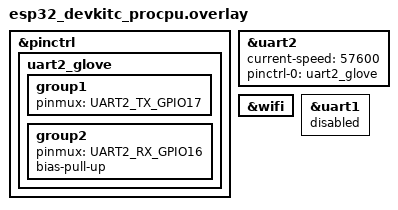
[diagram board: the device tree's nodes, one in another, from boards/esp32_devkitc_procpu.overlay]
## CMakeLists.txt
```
cmake_minimum_required(VERSION 3.20.0)

# tf-psa-crypto probes host pthreads by default. This is an embedded Zephyr
# cross-build, so disable that host-only package lookup for quieter CMake.
set(CMAKE_DISABLE_FIND_PACKAGE_Threads TRUE CACHE BOOL "" FORCE)

set(GLOVE_ZEPHYR_VERSION_FILE $ENV{ZEPHYR_BASE}/VERSION)
if(EXISTS "${GLOVE_ZEPHYR_VERSION_FILE}")
    file(STRINGS "${GLOVE_ZEPHYR_VERSION_FILE}" GLOVE_ZEPHYR_MAJOR_LINE
         REGEX "^VERSION_MAJOR = [0-9]+")
    string(REGEX REPLACE "^VERSION_MAJOR = ([0-9]+).*" "\\1"
           GLOVE_ZEPHYR_MAJOR "${GLOVE_ZEPHYR_MAJOR_LINE}")
    if(GLOVE_ZEPHYR_MAJOR GREATER_EQUAL 4)
        list(APPEND EXTRA_CONF_FILE
             "${CMAKE_CURRENT_SOURCE_DIR}/prj_zephyr4.conf")
    else()
        list(APPEND EXTRA_CONF_FILE
             "${CMAKE_CURRENT_SOURCE_DIR}/prj_zephyr3.conf")
    endif()
endif()

# MQTT/WiFi stay enabled in prj.conf. Secrets are loaded only from this local
# ignored file when present, so credentials never need to live in git.
set(GLOVE_LOCAL_CREDENTIALS_CONF ${CMAKE_CURRENT_SOURCE_DIR}/credentials.conf)
if(EXISTS ${GLOVE_LOCAL_CREDENTIALS_CONF})
    if(DEFINED EXTRA_CONF_FILE)
        list(APPEND EXTRA_CONF_FILE ${GLOVE_LOCAL_CREDENTIALS_CONF})
    else()
        set(EXTRA_CONF_FILE ${GLOVE_LOCAL_CREDENTIALS_CONF})
    endif()
endif()

find_package(Zephyr REQUIRED HINTS $ENV{ZEPHYR_BASE})
project(glove_esp32)

target_include_directories(app PRIVATE
    ${CMAKE_CURRENT_SOURCE_DIR}/include
    ${CMAKE_CURRENT_SOURCE_DIR}/../common/include
)

target_sources(app PRIVATE
    src/main.c
    src/gesture.c
    src/uart_stm32.c
    src/ble_adc.c
    src/calibration.c
    src/wifi_mqtt.c
    ../common/src/frame_protocol.c
)

target_compile_definitions(app PRIVATE
    FRAME_SECURE_TX_ID=0x45U  # 'E' = ESP32
    FRAME_SECURE_RX_ID=0x53U  # 'S' = STM32
)

# Embed CA certificates for MQTT TLS (only when CONFIG_GLOVE_MQTT_TLS=y)
if(CONFIG_GLOVE_MQTT_TLS)
    set(CERT_ROOT_SRC ${CMAKE_CURRENT_SOURCE_DIR}/certs/digicert_global_root_g2.pem)
    set(CERT_INTERMEDIATE_SRC ${CMAKE_CURRENT_SOURCE_DIR}/certs/geotrust_tls_rsa_ca_g1.pem)
    if(NOT EXISTS ${CERT_ROOT_SRC} OR NOT EXISTS ${CERT_INTERMEDIATE_SRC})
        message(FATAL_ERROR
            "MQTT TLS enabled but Adafruit IO CA chain certs are missing.\n"
            "Expected files in application/esp32_app/certs/.")
    endif()
    generate_inc_file_for_target(app
        ${CERT_ROOT_SRC}
        ${ZEPHYR_BINARY_DIR}/include/generated/digicert_global_root_g2.pem.inc
    )
    generate_inc_file_for_target(app
        ${CERT_INTERMEDIATE_SRC}
        ${ZEPHYR_BINARY_DIR}/include/generated/geotrust_tls_rsa_ca_g1.pem.inc
    )
    target_include_directories(app PRIVATE
        ${ZEPHYR_BINARY_DIR}/include/generated
    )
endif()
```

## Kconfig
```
# GloveAssist ESP32 - Application Kconfig
#
# WiFi and MQTT credentials are configured here.
# Override in prj.conf or via west build -DCONFIG_xxx=...

config GLOVE_WIFI_SSID
    string "WiFi network SSID"
    default ""
    help
      SSID of the WiFi access point to connect to.
      Used by the default Adafruit IO cloud build.

config GLOVE_WIFI_PASSWORD
    string "WiFi network password"
    default ""
    help
      WPA2 pre-shared key for the WiFi network.
      Only used when CONFIG_WIFI is enabled.

config GLOVE_MQTT_BROKER_HOST
    string "MQTT broker hostname"
    default "io.adafruit.com"
    help
      Hostname (or IP) of the MQTT broker.
      Final demo profile uses Adafruit IO over MQTT/TLS.

config GLOVE_MQTT_WEBSOCKET
    bool "Use MQTT over WebSocket"
    depends on MQTT_LIB_WEBSOCKET && WEBSOCKET_CLIENT
    default n
    help
      Use MQTT over WebSocket. For Adafruit IO this uses TLS on port 443
      with the /mqtt WebSocket path, useful when networks block port 8883.

config GLOVE_MQTT_BROKER_PORT
    int "MQTT broker port"
    default 443 if GLOVE_MQTT_WEBSOCKET
    default 8883 if GLOVE_MQTT_TLS
    default 1883
    range 1 65535
    help
      TCP port of the MQTT broker.
      Standard: 1883 (plain), 8883 (TLS), 443 (MQTT over WebSocket).

config GLOVE_MQTT_TLS
    bool "Enable TLS for MQTT connection"
    depends on MQTT_LIB_TLS
    default y
    help
      Use MQTT_TRANSPORT_SECURE (TLS 1.2/1.3) instead of plain TCP.
      Requires a CA certificate in application/esp32_app/certs/broker_ca.pem.
      Automatically sets default broker port to 8883.

config GLOVE_MQTT_TLS_SEC_TAG
    int "TLS credentials security tag for MQTT broker CA cert"
    depends on GLOVE_MQTT_TLS
    default 42
    help
      Zephyr TLS security tag used to register the broker CA certificate
      via tls_credential_add(). Must be unique across the application.

config GLOVE_MQTT_USERNAME
    string "MQTT broker username"
    default ""
    help
      Username for MQTT CONNECT authentication.
      For Adafruit IO: your Adafruit IO username (e.g. "johndoe").
      Leave empty only when using a broker profile that does not require auth.

config GLOVE_MQTT_PASSWORD
    string "MQTT broker password / API key"
    default ""
    help
      Password for MQTT CONNECT authentication.
      For Adafruit IO: your Adafruit IO Active Key (not account password).
      Leave empty for anonymous brokers.

config GLOVE_MQTT_AUTH
    bool "Enable MQTT username/password authentication"
    default n
    help
      Set to y when GLOVE_MQTT_USERNAME and GLOVE_MQTT_PASSWORD are provided.
      Enables MQTT CONNECT with credentials and Adafruit IO topic format.
      Enabled by prj.conf when Adafruit IO credentials are configured.

# Pull in Zephyr's Kconfig tree (REQUIRED - must be last)
source "Kconfig.zephyr"
```

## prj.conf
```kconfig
# ===========================================================================
# GloveAssist ESP32 - prj.conf
# Board:  esp32_devkitc_wroom/esp32/procpu
# Role:   Brain (gesture classification, BLE, WiFi, MQTT)
# ===========================================================================
#
# Phase 1  <- CURRENT: UART RX from STM32, log raw sensor data
# Phase 3  : Gesture classifier (threshold-based)
# Phase 4  : Send display commands to STM32 (OLED text)
# Phase 5  : Send haptic commands to STM32 (buzz/vibrate)
# Phase 6  : BLE NUS (Nordic UART Service)
# Phase 7  : WiFi + MQTT / Adafruit IO
# Phase 8  : Calibration support
#

# Kernel
CONFIG_MAIN_STACK_SIZE=4096
CONFIG_SYSTEM_WORKQUEUE_STACK_SIZE=2048
CONFIG_IDLE_STACK_SIZE=1024
CONFIG_ISR_STACK_SIZE=2048
CONFIG_HEAP_MEM_POOL_IGNORE_MIN=y

# GPIO
CONFIG_GPIO=y

# UART - STM32 communication UART2 (GPIO17 TX / GPIO16 RX)
# Polling mode; nu necesita UART_INTERRUPT_DRIVEN.
CONFIG_SERIAL=y

# BLE peripheral for LightBlue. Service: Nordic UART Service compatible UUIDs.
CONFIG_BT=y
CONFIG_BT_PERIPHERAL=y
CONFIG_BT_DEVICE_NAME="GloveAssist"
CONFIG_BT_MAX_CONN=1
# BLE NUS uses SMP passkey pairing with MITM protection. ESP32 displays the
# 6-digit passkey on the STM32 OLED via the secure UART command channel.
# Bonding is enabled so phone reconnects can reuse the authenticated LTK.
CONFIG_BT_SMP=y
CONFIG_BT_SMP_ENFORCE_MITM=y
# ESP32 RAM is very tight with WiFi+MQTT/TLS active. Zephyr defaults to
# Secure Connections-only pairing, which uses ECC and caused immediate BLE
# disconnects on this build. Secure Connections is still allowed when both
# peers can complete it, but it is not required. Passkey pairing targets
# BT_SECURITY_L3 authenticated link-layer encryption.
CONFIG_BT_SMP_SC_PAIR_ONLY=n
# Enable bonding so the LTK is stored in NVS via the settings subsystem.
# Without this, ESP32 never saves the LTK; on reconnect the phone sends its
# cached LTK, ESP32 rejects it (PIN_OR_KEY_MISSING) and SMP loops forever.
# BT_SETTINGS persists bond keys across reboots using the NVS/settings backend
# already configured below. After a firmware flash that clears NVS, the code
# detects PIN_OR_KEY_MISSING, calls bt_unpair(), disconnects, and the phone
# re-pairs cleanly on the next attempt.
CONFIG_BT_BONDABLE=y
CONFIG_BT_SETTINGS=y
CONFIG_BT_PRIVACY=n
CONFIG_BT_L2CAP_TX_MTU=65
CONFIG_BT_BUF_ACL_RX_SIZE=69
CONFIG_BT_BUF_ACL_TX_SIZE=69
CONFIG_BT_AUTO_DATA_LEN_UPDATE=n
CONFIG_BT_GAP_AUTO_UPDATE_CONN_PARAMS=n
CONFIG_BT_GATT_CACHING=n
CONFIG_BT_GATT_SERVICE_CHANGED=n
# BT RX thread: handles HCI events; SMP state machine runs here.
CONFIG_BT_RX_STACK_SIZE=3072
CONFIG_BT_ATT_PREPARE_COUNT=1
CONFIG_BT_MAX_PAIRED=1
CONFIG_BT_SECURITY_ERR_TO_STR=y

# Logging (ESP32 has USB-to-UART CP210x on UART0, separate from STM32 comm)
CONFIG_LOG=y
CONFIG_LOG_DEFAULT_LEVEL=3
CONFIG_LOG_BACKEND_UART=y
CONFIG_UART_CONSOLE=y
CONFIG_LOG_PROCESS_THREAD_STACK_SIZE=1536

# Boot banner
CONFIG_BOOT_BANNER=y

# NVS + Settings subsystem (calibration threshold persistence).
# SOC_FLASH_ESP32 is auto-selected by the SoC, but the generic Zephyr flash
# API layer (CONFIG_FLASH) and flash-map (CONFIG_FLASH_MAP) must be explicitly
# enabled — without them NVS/SETTINGS_NVS are silently dropped and Kconfig
# falls back to SETTINGS_NONE (a no-op backend that never writes to flash).
CONFIG_FLASH=y
CONFIG_FLASH_MAP=y
CONFIG_NET_BUF=y
CONFIG_NVS=y
CONFIG_SETTINGS=y
CONFIG_SETTINGS_NVS=y

# WiFi + MQTT cloud publishing to Adafruit IO.
CONFIG_WIFI=y
CONFIG_WIFI_ESP32=y
CONFIG_ESP32_WIFI_STA_AUTO_DHCPV4=y

CONFIG_NETWORKING=y
CONFIG_NET_L2_WIFI_MGMT=y
CONFIG_NET_IPV4=y
CONFIG_NET_IPV6=n
CONFIG_NET_DHCPV4=y
CONFIG_NET_SOCKETS=y
CONFIG_DNS_RESOLVER=y
CONFIG_NET_TCP=y
CONFIG_NET_UDP=y
CONFIG_SNTP=y

CONFIG_ESP32_WIFI_STATIC_RX_BUFFER_NUM=2
CONFIG_ESP32_WIFI_DYNAMIC_RX_BUFFER_NUM=3
CONFIG_ESP32_WIFI_DYNAMIC_TX_BUFFER_NUM=3
CONFIG_ESP32_WIFI_AMPDU_TX_ENABLED=n
CONFIG_ESP32_WIFI_AMPDU_RX_ENABLED=n

CONFIG_NET_MAX_CONN=4
CONFIG_NET_MAX_CONTEXTS=4
CONFIG_NET_BUF_RX_COUNT=8
# TLS MQTT publishes can need several chained TX buffers, especially during
# retransmission on mobile hotspots. Keep RX small, but give TX a little headroom.
CONFIG_NET_BUF_TX_COUNT=12
CONFIG_DNS_RESOLVER_MAX_SERVERS=1
CONFIG_NET_SOCKETS_CONNECT_TIMEOUT=5000

CONFIG_MQTT_LIB=y
CONFIG_MQTT_KEEPALIVE=60

CONFIG_MQTT_LIB_TLS=y
CONFIG_NET_SOCKETS_SOCKOPT_TLS=y
CONFIG_TLS_CREDENTIALS=y
CONFIG_MBEDTLS=y
CONFIG_MBEDTLS_HAVE_TIME_DATE=y
CONFIG_MBEDTLS_ENABLE_HEAP=y
# mbedTLS heap: Adafruit IO TLS/X.509 handshake needs >28KB (confirmed).
# Reduced from 40KB to 36KB to free 4KB of dram0 for the enlarged BT RX
# stack above. 36KB gives 8KB headroom above the confirmed minimum.
CONFIG_MBEDTLS_HEAP_SIZE=36864
# Main heap 40KB: WiFi adapter functioneaza la 40KB (OOM la 32KB confirmat).
CONFIG_HEAP_MEM_POOL_SIZE=40960
# Adafruit IO trimite leaf + intermediate cert in handshake (>2KB).
# Valoarea minima necesara pentru a nu primi MBEDTLS_ERR_SSL_BUFFER_TOO_SMALL
# care aparea ca -113 ECONNABORTED la mqtt_connect().
CONFIG_MBEDTLS_SSL_MAX_CONTENT_LEN=8192
CONFIG_MBEDTLS_SSL_DTLS_CONNECTION_ID=n

CONFIG_GLOVE_MQTT_TLS=y
CONFIG_GLOVE_MQTT_BROKER_HOST="io.adafruit.com"
CONFIG_GLOVE_MQTT_BROKER_PORT=8883

# Logging TLS: temporar y pentru a vedea "TLS handshake error: -0x%x"
CONFIG_NET_LOG=y
CONFIG_PRINTK=y
CONFIG_THREAD_NAME=n
CONFIG_INIT_STACKS=n
```

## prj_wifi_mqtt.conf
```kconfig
# ===========================================================================
# GloveAssist ESP32 - WiFi + MQTT cloud profile
#
# Usage:
#   west build ... -- -DEXTRA_CONF_FILE=prj_wifi_mqtt.conf
#
# TLS (port 8883) is ENABLED by default in this profile.
# Plain TCP (port 1883): comment out the TLS block below.
#
# Set your actual credentials before building:
#   CONFIG_GLOVE_WIFI_SSID, CONFIG_GLOVE_WIFI_PASSWORD
#   For authenticated brokers: CONFIG_GLOVE_MQTT_USERNAME / PASSWORD (add to Kconfig)
# ===========================================================================

# WiFi driver (ESP32 built-in)
CONFIG_WIFI=y
CONFIG_WIFI_ESP32=y
CONFIG_ESP32_WIFI_STA_AUTO_DHCPV4=y

# Network stack
CONFIG_NETWORKING=y
CONFIG_NET_L2_WIFI_MGMT=y
CONFIG_NET_IPV4=y
CONFIG_NET_DHCPV4=y
CONFIG_NET_SOCKETS=y
CONFIG_NET_SOCKETS_POSIX_NAMES=y
CONFIG_DNS_RESOLVER=y
CONFIG_NET_TCP=y
CONFIG_NET_UDP=y

# MQTT
CONFIG_MQTT_LIB=y
CONFIG_MQTT_KEEPALIVE=60

# ---------------------------------------------------------------------------
# TLS block — comment out to use plain TCP on port 1883
# ---------------------------------------------------------------------------
CONFIG_MQTT_LIB_TLS=y
CONFIG_NET_SOCKETS_SOCKOPT_TLS=y
CONFIG_TLS_CREDENTIALS=y
CONFIG_MBEDTLS=y
CONFIG_MBEDTLS_TLS_VERSION_1_2=y
CONFIG_MBEDTLS_CIPHER_AES_ENABLED=y
CONFIG_MBEDTLS_KEY_EXCHANGE_RSA_ENABLED=y
CONFIG_MBEDTLS_KEY_EXCHANGE_ECDHE_RSA_ENABLED=y
CONFIG_MBEDTLS_KEY_EXCHANGE_ECDHE_ECDSA_ENABLED=y
CONFIG_MBEDTLS_SHA256_ENABLED=y
CONFIG_MBEDTLS_SHA512_ENABLED=y
CONFIG_MBEDTLS_ECP_DP_SECP256R1_ENABLED=y
CONFIG_MBEDTLS_ECP_DP_SECP384R1_ENABLED=y
CONFIG_GLOVE_MQTT_TLS=y
CONFIG_GLOVE_MQTT_BROKER_PORT=8883
# ---------------------------------------------------------------------------

# Credentials — CHANGE THESE
CONFIG_GLOVE_WIFI_SSID="YourSSID"
CONFIG_GLOVE_WIFI_PASSWORD="YourPassword"
CONFIG_GLOVE_MQTT_BROKER_HOST="test.mosquitto.org"

# Increase heap for TLS handshake buffers (~16 KB needed)
CONFIG_HEAP_MEM_POOL_SIZE=98304
CONFIG_MAIN_STACK_SIZE=8192
CONFIG_SYSTEM_WORKQUEUE_STACK_SIZE=4096

# MbedTLS heap (used during TLS handshake)
CONFIG_MBEDTLS_HEAP_SIZE=16384

# Logging
CONFIG_NET_LOG=n
CONFIG_WIFI_LOG_LEVEL_WRN=y
```

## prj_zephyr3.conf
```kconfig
# Extra options for Zephyr 3.7.
#
# The Zephyr 3.7 ESP32 WiFi stack pulls in ESP-IDF headers that expect
# POSIX/newlib time types such as suseconds_t.
CONFIG_NEWLIB_LIBC=y
CONFIG_NET_L2_ETHERNET=y
CONFIG_HEAP_MEM_POOL_SIZE=16384

# Zephyr 3.7 places WiFi, BT, TLS heaps and thread stacks in ESP32 DRAM0.
# Keep these tighter than the Zephyr 4.x local/dev profile so the CI artifact
# links with WiFi + BLE + MQTT/TLS enabled.
CONFIG_MAIN_STACK_SIZE=3072
CONFIG_BT_RX_STACK_SIZE=2560
CONFIG_LOG_PROCESS_THREAD_STACK_SIZE=1024
CONFIG_NET_MGMT_EVENT_STACK_SIZE=1024
CONFIG_NET_RX_STACK_SIZE=1536
CONFIG_NET_TCP_WORKQ_STACK_SIZE=1536
CONFIG_MBEDTLS_HEAP_SIZE=24576
CONFIG_MBEDTLS_SSL_MAX_CONTENT_LEN=4096

# Zephyr 3.7 uses the older mbedTLS Kconfig names for these TLS features.
CONFIG_MBEDTLS_TLS_VERSION_1_2=y
CONFIG_MBEDTLS_ECP_C=y
CONFIG_MBEDTLS_ECDH_C=y
CONFIG_MBEDTLS_ECP_DP_SECP256R1_ENABLED=y
CONFIG_MBEDTLS_KEY_EXCHANGE_ECDHE_RSA_ENABLED=y
CONFIG_MBEDTLS_PEM_CERTIFICATE_FORMAT=y
CONFIG_MBEDTLS_SERVER_NAME_INDICATION=y

CONFIG_POSIX_TIMERS=y
```

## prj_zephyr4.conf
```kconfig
# Extra options for Zephyr 4.x and newer.
#
# P-256 ECC for Secure Connections runs in the BT Long Work Queue thread.
# Zephyr 4.x exposes this stack-size symbol as user-configurable; Zephyr 3.7
# keeps it hidden, so the common prj.conf must not assign it.
CONFIG_BT_LONG_WQ_STACK_SIZE=4096

CONFIG_BT_TX_PROCESSOR_STACK_SIZE=1024

# TLS 1.2 only: Adafruit IO accepts ECDHE-RSA-AES128-GCM-SHA256 on 8883.
# Keep the cipher list tight to reduce mbedTLS RAM/code pressure on ESP32.
CONFIG_MBEDTLS_CIPHERSUITE_TLS_ECDHE_RSA_WITH_AES_128_GCM_SHA256=y
CONFIG_MBEDTLS_PEM_PARSE_C=y
CONFIG_MBEDTLS_SSL_SERVER_NAME_INDICATION=y
CONFIG_NET_SOCKETS_TLS_CONNECT_TIMEOUT=20000

# Zephyr 4.4.0-rc1 / mbedTLS 4.0 (tf-psa-crypto) Kconfig bug:
# Kconfig.ciphersuites selects RSA key-pair types but omits RSA_PUBLIC_KEY.
CONFIG_PSA_WANT_KEY_TYPE_RSA_PUBLIC_KEY=y

# Keep ECDHE on secp256r1 / P-256 and avoid ESP32's partial PSA ECC accel,
# which produced MBEDTLS_ERR_SSL_HW_ACCEL_FAILED during TLS handshake.
CONFIG_MBEDTLS_PSA_P256M_DRIVER_ENABLED=n
```

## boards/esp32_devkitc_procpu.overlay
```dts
/*
 * GloveAssist ESP32 Board Overlay
 * Board: esp32_devkitc/esp32/procpu (newer Zephyr local workspaces)
 *
 * UART topology:
 *   UART0 (GPIO1/GPIO3)   -> console / logging (CP210x USB, COM11)
 *   UART2 (GPIO17 TX / GPIO16 RX) <- STM32 USART1 (PA9 TX -> GPIO16 RX)
 *
 * UART2 native pins: GPIO17=TX, GPIO16=RX, no SPI flash conflict.
 */

&pinctrl {
	uart2_glove: uart2_glove {
		group1 {
			pinmux = <UART2_TX_GPIO17>;
		};
		group2 {
			pinmux = <UART2_RX_GPIO16>;
			bias-pull-up;
		};
	};
};

/* UART2: STM32 inter-MCU @ 57600 baud. */
&uart2 {
	status = "okay";
	current-speed = <57600>;
	pinctrl-0 = <&uart2_glove>;
	pinctrl-names = "default";
};

&wifi {
	status = "okay";
};

/* UART1: pini default GPIO9/GPIO10 = SPI flash intern, dezactivat */
&uart1 {
	status = "disabled";
};
```

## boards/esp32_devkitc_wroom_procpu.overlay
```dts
/*
 * Zephyr 3.7 board name for ESP32 DevKitC WROOM.
 *
 * Keep the pin mapping in one place; newer local workspaces may still pick up
 * esp32_devkitc_procpu.overlay automatically.
 */

#include "esp32_devkitc_procpu.overlay"
```

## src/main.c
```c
/*
 * GloveAssist ESP32 - Main Application
 *
 * Coordinates 3 modules:
 *   uart_stm32 : UART2 communication with STM32 (TX/RX frames)
 *   gesture    : Threshold-based flex sensor gesture classifier
 *   ble_adc    : BLE NUS peripheral (notify phone, receive caregiver ACK)
 *
 * Main loop:
 *   - Receives SENSOR_RAW frames from STM32 via UART2
 *   - Classifies gesture with compose + 1000ms stability filter
 *   - Notifies BLE phone with gesture name and publishes over MQTT
 *   - Sends HEARTBEAT to STM32 every 1000ms
 *   - On BLE caregiver "OK" -> uart_stm32_send_caregiver_ack()
 *     -> STM32 plays OLED + buzzer + motor feedback
 */

#include <zephyr/kernel.h>
#include <zephyr/logging/log.h>
#include <zephyr/random/random.h>
#include <esp_random.h>
#include <stdio.h>
#include <string.h>

#include "frame_protocol.h"
#include "gesture.h"
#include "uart_stm32.h"
#include "ble_adc.h"
#include "calibration.h"
#include "wifi_mqtt.h"

LOG_MODULE_REGISTER(esp32_main, LOG_LEVEL_INF);

#define HEARTBEAT_PERIOD_MS  1000U
#define STATUS_REPORT_MS     3000U
#define STM32_FRAME_TIMEOUT_MS 3000U
#define RAW_LOG_COUNT          16U
#define GESTURE_RETRIGGER_MS 5000U  /* dupa 5s, acelasi gest poate re-triggera */
#define GESTURE_COMPOSE_COUNT   5U  /* N frame-uri consecutive inainte de debounce (100ms la 50Hz) */
#define RECAL_HOLD_MS       20000U  /* pumn inchis 20s continuu -> recalibrare */

/* -- Link statistics ---------------------------------------------------- */
static uint32_t s_total_frames;
static uint32_t s_bad_frames;
static uint32_t s_total_bytes;
static uint32_t s_seq_gaps;
static uint8_t  s_last_seq    = 0xFFU; /* 0xFF = no frame yet */

/* -- Gesture stability filter state ------------------------------------- */
static gesture_id_t s_last_stable_gesture;
static gesture_id_t s_pending_gesture;
static uint32_t     s_gesture_stable_since;
static uint32_t     s_last_stable_time;   /* moment ultimului gest raportat */
static bool         s_midpoint_buzzed;    /* buzz de progres la 1s */

/* Compose window: N consecutive frames must agree before debounce starts */
static gesture_id_t s_compose_gesture = GESTURE_NONE;
static uint8_t      s_compose_count   = 0U;

/* -- Fist-hold recalibration tracker ------------------------------------ */
static uint32_t s_fist_hold_start = 0U;  /* 0 = fist not currently tracked */
static bool     s_recal_requested = false;

/* -- First-boot calibration flag ---------------------------------------- */
static bool s_need_calibration = false;  /* set if no NVS profiles found */

/* -- Last ADC snapshot (used for calibration; BLE runtime sends gestures only) */
static uint16_t s_last_adc[4];

/* -- UART session handshake state --------------------------------------- */
static uint32_t s_session_nonce;       /* nonce sent to STM32 in SESSION_HELLO */
static uint32_t s_session_retry_ts;   /* timestamp of last SESSION_HELLO send  */
static uint32_t s_last_stm32_rx_ts;   /* last valid frame received from STM32   */
static bool     s_session_established;
static frame_hmac_parser_t s_uart_parser;
#define SESSION_RETRY_MS  2000U        /* resend SESSION_HELLO every 2s until ACK */

/* -- Internal helpers --------------------------------------------------- */

static void reset_gesture_pipeline(void)
{
    s_last_stable_gesture = GESTURE_NONE;
    s_pending_gesture = GESTURE_NONE;
    s_gesture_stable_since = 0U;
    s_last_stable_time = 0U;
    s_midpoint_buzzed = false;
    s_compose_gesture = GESTURE_NONE;
    s_compose_count = 0U;
    s_fist_hold_start = 0U;
    s_recal_requested = false;
}

static void check_seq(uint8_t seq)
{
    if (s_last_seq == 0xFFU) {
        s_last_seq = seq;
        return;
    }
    uint8_t expected = (uint8_t)(s_last_seq + 1U);
    if (seq != expected) {
        s_seq_gaps++;
        LOG_WRN("SEQ gap: expected %u got %u", expected, seq);
    }
    s_last_seq = seq;
}

static void start_uart_session(uint32_t now, const char *reason)
{
    uint32_t nonce;

    nonce = esp_random();  /* hardware RNG — zgomot termic real, nu pseudo-random */
    if (nonce == 0U) {
        nonce = 0xA5C37B29U;
    }

    s_session_nonce = nonce;
    s_session_retry_ts = now;
    s_last_stm32_rx_ts = now;
    s_session_established = false;
    s_last_seq = 0xFFU;

    frame_secure_set_session(nonce);
    frame_hmac_parser_init(&s_uart_parser);
    reset_gesture_pipeline();
    uart_stm32_send_session_hello(nonce);

    if (reason != NULL) {
        LOG_WRN("%s (nonce=0x%08x)", reason, nonce);
    } else {
        LOG_INF("UART secure session start (nonce=0x%08x)", nonce);
    }
}

static void handle_sensor_frame(const frame_t *f)
{
    uint16_t adc[4];

    frame_decode_sensor_payload(f->payload, &adc[0], &adc[1], &adc[2], &adc[3]);
    s_session_established = true;
    check_seq(f->seq);
    s_total_frames++;
    uart_stm32_send_ack(f->seq);

    /* Keep latest ADC values for calibration display and profile sampling. */
    s_last_adc[0] = adc[0];
    s_last_adc[1] = adc[1];
    s_last_adc[2] = adc[2];
    s_last_adc[3] = adc[3];

    /*
     * During calibration: skip gesture classification entirely.
     * The calibration module reads ADC values via calibration_update() in
     * the main loop; we must not interfere with gesture state here.
     */
    if (calibration_active()) {
        return;
    }

    gesture_id_t g   = gesture_classify(adc);
    uint32_t     now = k_uptime_get_32();

    /*
     * Fist-hold recalibration tracker (checked before compose window).
     * If GESTURE_HELP (full fist) is classified continuously for RECAL_HOLD_MS,
     * set s_recal_requested flag for the main loop to handle.
     */
    if (g == GESTURE_HELP) {
        if (s_fist_hold_start == 0U) {
            s_fist_hold_start = now;
        } else if (!calibration_active()
                   && ((now - s_fist_hold_start) >= RECAL_HOLD_MS)) {
            s_fist_hold_start = 0U;
            s_recal_requested = true;
            LOG_INF("Fist held %u ms -> recalibration triggered", RECAL_HOLD_MS);
        }
    } else {
        s_fist_hold_start = 0U;  /* reset on any non-fist gesture */
    }

    /*
     * Compose window: GESTURE_COMPOSE_COUNT consecutive frames must
     * return the same gesture before we start the stability timer.
     * This eliminates single-frame spikes and transition noise.
     */
    if (g != s_compose_gesture) {
        s_compose_gesture = g;
        s_compose_count   = 1U;
        return; /* reset compose - don't advance stability timer */
    }
    if (s_compose_count < GESTURE_COMPOSE_COUNT) {
        s_compose_count++;
        return; /* still composing */
    }

    /* Composed gesture confirmed - run stability/debounce tracker */
    if (g != s_pending_gesture) {
        s_pending_gesture      = g;
        s_gesture_stable_since = now;
        s_midpoint_buzzed      = false;
    } else if (g != GESTURE_NONE) {
        uint32_t stable_ms = now - s_gesture_stable_since;
        /* Buzz la 1s: feedback de progres ("inca un pic") */
        if (!s_midpoint_buzzed && (stable_ms >= (GESTURE_STABLE_MS / 2U))) {
            s_midpoint_buzzed = true;
            uart_stm32_send_haptic_buzz(30U);
        }
    }
    if ((g != GESTURE_NONE)
               && (g == s_pending_gesture)
               && ((g != s_last_stable_gesture)
                   || ((now - s_last_stable_time) >= GESTURE_RETRIGGER_MS))
               && ((now - s_gesture_stable_since) >= GESTURE_STABLE_MS)) {
        s_last_stable_gesture = g;
        s_last_stable_time    = now;
        LOG_INF("GESTURE: %s (id=%u)  adc %u %u %u %u",
                gesture_name(g), (unsigned)g,
                adc[0], adc[1], adc[2], adc[3]);
        /* Local feedback has priority: patient confirmation should not wait
         * behind BLE notifications or cloud publishing. */
        uart_stm32_send_gesture_feedback((uint8_t)g);
        ble_adc_set_last_gesture(g);
        (void)ble_adc_send_gesture(g, adc);
        (void)wifi_mqtt_publish_gesture(g);
        (void)wifi_mqtt_publish_status(gesture_name(g));
    }
}

static void handle_frame(const frame_t *f)
{
    s_last_stm32_rx_ts = k_uptime_get_32();

    switch ((frame_type_t)f->type) {
    case FRAME_TYPE_SENSOR_RAW:
        handle_sensor_frame(f);
        break;
    case FRAME_TYPE_HEARTBEAT:
        uart_stm32_send_ack(f->seq);
        break;
    case FRAME_TYPE_STATUS:
        if (f->payload[0] == (uint8_t)STATUS_ERR) {
            if ((f->payload[1] | f->payload[2] | f->payload[3]) != 0U) {
                LOG_WRN("STM32 sensor fault: active=0x%02x low=0x%02x high=0x%02x",
                        f->payload[1], f->payload[2], f->payload[3]);
            } else {
                LOG_INF("STM32 sensor fault cleared");
            }
        } else {
            LOG_INF("STM32 status: 0x%02x", f->payload[0]);
        }
        break;
    case FRAME_TYPE_SESSION:
        /* SESSION_ACK from STM32: session handshake confirmed. */
        if (f->payload[0] == (uint8_t)SESSION_ACK) {
            s_session_established = true;
            s_last_seq = 0xFFU;
            LOG_INF("UART secure session established (STM32 ACK received)");
        }
        break;
    default:
        break;
    }
}

static void log_link_status(void)
{
    if (s_total_frames > 0U) {
        LOG_INF("Link: %u frames  %u bad  %u gaps  %u bytes",
                s_total_frames, s_bad_frames, s_seq_gaps, s_total_bytes);
    } else {
        LOG_WRN("No frames yet (bytes=%u bad=%u)", s_total_bytes, s_bad_frames);
    }
}

/* -- Main --------------------------------------------------------------- */
int main(void)
{
    LOG_INF("=== GloveAssist ESP32 ===");

    if (uart_stm32_init() != 0) {
        LOG_ERR("UART STM32 init failed");
        return -1;
    }

    start_uart_session(k_uptime_get_32(), NULL);

    bool ble_ready = false;
    if (ble_adc_init() != 0) {
        LOG_WRN("BLE init failed or disabled — continuing without BLE");
        /* Non-fatal: UART+WiFi+MQTT still work. BLE stubs return 0. */
    } else {
        ble_ready = true;
    }

    /*
     * Load saved per-gesture profiles from NVS.
     * Extract per-finger open/fist values for the hysteresis classifier:
     *   open[i]  = NONE phase   (all fingers extended)
     *   fist[0]  = WATER phase  (index  finger bent)
     *   fist[1]  = WC    phase  (middle finger bent)
     *   fist[2]  = FOOD  phase  (ring   finger bent)
     *   fist[3]  = HELP  phase  (pinky  finger bent)
     */
    {
        uint16_t saved_profiles[CALIB_NUM_GESTURES][CALIB_NUM_FINGERS];
        if (calibration_init(saved_profiles) != 0) {
            s_need_calibration = true;
            LOG_INF("First boot: no calibration data. Will auto-calibrate.");
        } else {
            uint16_t open_p[4], fist_p[4];
            for (uint8_t i = 0U; i < 4U; i++) {
                open_p[i] = saved_profiles[0][i]; /* NONE: all extended */
            }
            fist_p[0] = saved_profiles[1][0]; /* WATER: index  bent */
            fist_p[1] = saved_profiles[2][1]; /* WC:    middle bent */
            fist_p[2] = saved_profiles[3][2]; /* FOOD:  ring   bent */
            fist_p[3] = saved_profiles[4][3]; /* HELP:  pinky  bent */
            gesture_set_profiles(open_p, fist_p);
            LOG_INF("Gesture profiles loaded from NVS");
        }
    }

    /* Start WiFi+MQTT (no-op in BLE-only builds). */
    (void)wifi_mqtt_init();

    LOG_INF("Init OK. Waiting for STM32 frames on UART2...");
    if (ble_ready) {
        LOG_INF("BLE ready for phone connection");
    }

    frame_hmac_parser_init(&s_uart_parser);

    uint32_t last_hb_tx    = k_uptime_get_32();
    uint32_t last_report   = k_uptime_get_32();
    uint8_t  raw_log_count = 0U;

    while (1) {
        uint32_t now = k_uptime_get_32();
        uint8_t  b;

        ble_adc_process();

        if (s_session_established && ((now - last_hb_tx) >= HEARTBEAT_PERIOD_MS)) {
            last_hb_tx = now;
            uart_stm32_send_heartbeat();
        }

        if (s_session_established
            && ((now - s_last_stm32_rx_ts) >= STM32_FRAME_TIMEOUT_MS)) {
            start_uart_session(now, "STM32 link quiet - restarting UART session handshake");
        }

        /* Retry SESSION_HELLO until the current STM32 session is confirmed.
         * This also recovers when STM32 resets/flashes while ESP32 stays on. */
        if (!s_session_established && ((now - s_session_retry_ts) >= SESSION_RETRY_MS)) {
            s_session_retry_ts = now;
            uart_stm32_send_session_hello(s_session_nonce);
            LOG_DBG("SESSION_HELLO retry (nonce=0x%08x)", s_session_nonce);
        }

        if ((now - last_report) >= STATUS_REPORT_MS) {
            last_report = now;
            log_link_status();
        }

        /* Calibration request from BLE ('C'). */
        if (ble_adc_pop_calibration_request()) {
            if (calibration_active()) {
                (void)ble_adc_send_text("CALIB: active\n");
            } else if (s_total_frames == 0U) {
                (void)ble_adc_send_text("CALIB: no sensor\n");
                LOG_WRN("Calibration requested but no STM32 frames yet");
            } else {
                LOG_INF("BLE: starting calibration");
                uart_stm32_send_oled_text("CALIBR");
                uart_stm32_send_haptic_buzz(150U);
                calibration_start();
                (void)ble_adc_send_text("CALIB: starting\n");
            }
        }

        /*
         * Auto-calibration: first boot or missing NVS profiles.
         * Wait until at least one STM32 frame has arrived (sensors warm-up),
         * then start calibration automatically.
         */
        if (s_need_calibration && !calibration_active() && (s_total_frames > 0U)) {
            s_need_calibration = false;
            LOG_INF("Auto-starting calibration (first boot / no profiles)");
            uart_stm32_send_oled_text("CALIBR");
            uart_stm32_send_haptic_buzz(150U);
            uart_stm32_send_haptic_vibrate(200U);
            (void)ble_adc_send_text("CALIB: starting\n");
            calibration_start();
        }

        /*
         * Fist held 20s: trigger recalibration.
         * Flag is set by handle_sensor_frame when GESTURE_HELP held for RECAL_HOLD_MS.
         */
        if (s_recal_requested && !calibration_active()) {
            s_recal_requested = false;
            LOG_INF("Fist 20s held -> starting recalibration");
            uart_stm32_send_oled_text("RECAL");
            uart_stm32_send_haptic_buzz(200U);
            uart_stm32_send_haptic_vibrate(300U);
            (void)ble_adc_send_text("CALIB: starting\n");
            calibration_start();
        }

        /*
         * Caregiver ACK: caregiver sent "ok" / digit via BLE.
         * Forward to STM32 (OLED "Understood" + haptic), notify BLE side.
         * NOTE: ACK is processed regardless of whether a gesture was active —
         * if gesture is NONE the STM32 still plays the confirmation feedback.
         */
        {
            gesture_id_t ack_g = GESTURE_NONE;
            if (ble_adc_pop_caregiver_ack_request(&ack_g)) {
                uart_stm32_send_caregiver_ack((uint8_t)ack_g);
                (void)ble_adc_send_text("Understood\n");
                LOG_INF("Caregiver ACK: gesture %u -> STM32 + BLE", (unsigned)ack_g);
            }
        }

        /* Run calibration update if active. */
        if (calibration_active()) {
            /*
             * Phase-change detection + countdown 3-2-1.
             * OLED is driven by periodic CMD_OLED_CALIB (every 200ms) which shows
             * phase label + countdown + live ADC values on all 4 OLED rows.
             * Haptic (buzz + vibrate) fires on phase transitions and countdown ticks.
             */
            const char *phase_str = calibration_status_line();
            static const char *s_last_phase_str;
            static uint32_t    s_calib_phase_ts  = 0U;
            static uint32_t    s_calib_oled_ts   = 0U;
            static int8_t      s_calib_cnt        = -1;

            if (phase_str != s_last_phase_str) {
                s_last_phase_str = phase_str;
                s_calib_phase_ts = now;
                s_calib_cnt      = 3;
                /* Tell user which gesture to hold (P: = phase instruction). */
                char pmsg[20];
                (void)snprintf(pmsg, sizeof(pmsg), "P:%s\n", phase_str);
                (void)ble_adc_send_text(pmsg);
                uart_stm32_send_haptic_buzz(80U);
                uart_stm32_send_haptic_vibrate(100U);
                (void)ble_adc_send_text("CALIB:3\n");
            }

            /* Non-blocking countdown: 3 → 2 → 1 → TINE! — haptic only, OLED via periodic */
            if (s_calib_cnt >= 0) {
                uint32_t settle_el = now - s_calib_phase_ts;
                int8_t target_cnt;

                if (settle_el < (CALIB_SETTLE_MS / 3U)) {
                    target_cnt = 3;
                } else if (settle_el < ((CALIB_SETTLE_MS * 2U) / 3U)) {
                    target_cnt = 2;
                } else if (settle_el < CALIB_SETTLE_MS) {
                    target_cnt = 1;
                } else {
                    target_cnt = 0;
                }

                if (target_cnt < s_calib_cnt) {
                    s_calib_cnt = target_cnt;
                    if (target_cnt == 2) {
                        uart_stm32_send_haptic_buzz(60U);
                        uart_stm32_send_haptic_vibrate(80U);
                        (void)ble_adc_send_text("CALIB:2\n");
                    } else if (target_cnt == 1) {
                        uart_stm32_send_haptic_buzz(60U);
                        uart_stm32_send_haptic_vibrate(80U);
                        (void)ble_adc_send_text("CALIB:1\n");
                    } else {
                        uart_stm32_send_haptic_buzz(200U);
                        uart_stm32_send_haptic_vibrate(350U);
                        (void)ble_adc_send_text("CALIB:HOLD\n");
                    }
                }
            }

            /* Periodic OLED update (200ms): gesture name + countdown + live ADC.
             * state = phase * 4 + countdown_step (0-19, maps to 5 gestures × 4 steps). */
            if ((now - s_calib_oled_ts) >= 200U) {
                s_calib_oled_ts = now;
                uint8_t phase_n = calibration_current_phase();
                uint8_t step_n  = (s_calib_cnt == 3) ? 0U :
                                  (s_calib_cnt == 2) ? 1U :
                                  (s_calib_cnt == 1) ? 2U : 3U;
                uart_stm32_send_calib_adc((uint8_t)(phase_n * 4U + step_n), s_last_adc);
            }

            uint16_t new_profiles[CALIB_NUM_GESTURES][CALIB_NUM_FINGERS];
            int rc = calibration_update(s_last_adc, new_profiles);

            if (rc >= 1 && rc <= (int)CALIB_NUM_GESTURES) {
                /* One phase completed — play OK sound, next phase starts automatically. */
                uart_stm32_send_haptic_buzz(120U);
                uart_stm32_send_haptic_vibrate(180U);
                (void)ble_adc_send_text("CALIB: phase OK\n");
                LOG_INF("Calibration phase %d done, starting next", rc);
            } else if (rc == 10) {
                /* All 5 gestures calibrated — extract per-finger values and apply. */
                uint16_t open_p[4], fist_p[4];
                for (uint8_t i = 0U; i < 4U; i++) {
                    open_p[i] = new_profiles[0][i]; /* NONE: extended */
                }
                fist_p[0] = new_profiles[1][0]; /* WATER: index  bent */
                fist_p[1] = new_profiles[2][1]; /* WC:    middle bent */
                fist_p[2] = new_profiles[3][2]; /* FOOD:  ring   bent */
                fist_p[3] = new_profiles[4][3]; /* HELP:  pinky  bent */
                gesture_set_profiles(open_p, fist_p);
                int save_rc = calibration_save(new_profiles);
                if (save_rc != 0) {
                    LOG_ERR("NVS save failed: %d — profiles applied but not persisted", save_rc);
                    uart_stm32_send_oled_text("SAVERR");
                    (void)ble_adc_send_text("CALIB:SAVERR\n");
                } else {
                    uart_stm32_send_oled_text("SAVED!");
                    (void)ble_adc_send_text("CALIB:saved\n");
                    LOG_INF("Calibration complete: all gestures saved to NVS");
                }
                uart_stm32_send_haptic_buzz(300U);
                uart_stm32_send_haptic_vibrate(400U);
                (void)ble_adc_send_text("CALIB:done\n");
                s_calib_cnt = -1;
            }
        }

        if (uart_stm32_poll_byte(&b) != 0) {
            k_usleep(200U);
            continue;
        }

        s_total_bytes++;
        if (raw_log_count < RAW_LOG_COUNT) {
            LOG_INF("rx[%u]=0x%02x", raw_log_count, b);
            raw_log_count++;
        }

        frame_hmac_t hf;
        int rc = frame_hmac_parser_push_byte(&s_uart_parser, b, &hf);

        if (rc == 1) {
            handle_frame(&hf.base);
        } else if (rc == -2) {
            s_bad_frames++;
        }
    }

    return 0;
}
```

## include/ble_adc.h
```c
#ifndef BLE_ADC_H
#define BLE_ADC_H

#include <stdint.h>
#include "frame_protocol.h"
#include <stdbool.h>

#if defined(CONFIG_BT)

int  ble_adc_init(void);
int  ble_adc_send_values(const uint16_t adc[4]);
int  ble_adc_send_gesture(gesture_id_t gesture, const uint16_t adc[4]);
void ble_adc_process(void);

/** Send a raw text notification over BLE NUS TX (max 20 bytes). */
int  ble_adc_send_text(const char *text);

/* Called by main after a stable gesture is detected. */
void ble_adc_set_last_gesture(gesture_id_t g);

/**
 * @brief Returns true once if BLE caregiver sent calibrate command ('C'/'c').
 * Clears the flag on read.
 */
bool ble_adc_pop_calibration_request(void);

/**
 * @brief Checks if caregiver sent OK/ACK via BLE. Clears the flag on read.
 * @param out_gesture  Filled with the gesture that was active when OK was
 *                     pressed (may be GESTURE_NONE if no gest was active).
 * @return true if an ACK was pending, false otherwise.
 * Main loop must handle: send CMD_CAREGIVER_ACK to STM32 and BLE
 * "Understood" notification back to phone.
 */
bool ble_adc_pop_caregiver_ack_request(gesture_id_t *out_gesture);

#else /* CONFIG_BT not set — provide no-op stubs */

#include "gesture.h"

static inline int  ble_adc_init(void)                                            { return 0; }
static inline int  ble_adc_send_values(const uint16_t *a)                        { (void)a; return 0; }
static inline int  ble_adc_send_gesture(gesture_id_t g, const uint16_t *a)       { (void)g; (void)a; return 0; }
static inline void ble_adc_process(void)                                         {}
static inline int  ble_adc_send_text(const char *t)                              { (void)t; return 0; }
static inline void ble_adc_set_last_gesture(gesture_id_t g)                      { (void)g; }
static inline bool ble_adc_pop_calibration_request(void)                         { return false; }
static inline bool ble_adc_pop_caregiver_ack_request(gesture_id_t *out)     { if(out){*out=GESTURE_NONE;} return false; }

#endif /* CONFIG_BT */

#endif /* BLE_ADC_H */
```

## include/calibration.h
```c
/*
 * calibration.h - Per-gesture flex sensor calibration for GloveAssist.
 *
 * Calibrates each gesture individually in sequence:
 *   Phase 0: NONE  (all fingers open/extended — resting position)
 *   Phase 1: WATER (index bent, rest open)
 *   Phase 2: WC    (index + middle bent)
 *   Phase 3: FOOD  (index + middle + ring bent)
 *   Phase 4: HELP  (all bent — full fist)
 *
 * Each phase: CALIB_SETTLE_MS prep + CALIB_PHASE_MS sampling.
 * Profiles saved under NVS key "calib/prof5".
 *
 * Bump CALIB_SCHEMA_VER whenever profiles format or gesture set changes.
 */

#ifndef CALIBRATION_H
#define CALIBRATION_H

#include <stdint.h>
#include <stdbool.h>

#define CALIB_NUM_GESTURES  5U    /* NONE + 4 functional gestures             */
#define CALIB_NUM_FINGERS   4U    /* index, middle, ring, pinky               */
#define CALIB_SETTLE_MS  4000U    /* user prep time per gesture (3-2-1 @ 1.3s)*/
#define CALIB_PHASE_MS   5000U    /* effective sampling time per gesture       */
#define CALIB_SCHEMA_VER    5U    /* v5: per-gesture profiles (5 × 4 uint16)  */

/**
 * @brief Load saved per-gesture profiles from NVS.
 *
 * Must be called once during boot after settings_subsys_init().
 *
 * @param profiles_out  [CALIB_NUM_GESTURES][CALIB_NUM_FINGERS] — filled on success.
 * @return  0         : profiles loaded, profiles_out is valid.
 *          -ENODATA  : no saved data (calibrate first).
 *          other < 0 : settings subsystem error.
 */
int calibration_init(uint16_t profiles_out[CALIB_NUM_GESTURES][CALIB_NUM_FINGERS]);

/**
 * @brief Persist per-gesture profiles to NVS flash.
 * @return 0 on success, negative errno on failure.
 */
int calibration_save(const uint16_t profiles[CALIB_NUM_GESTURES][CALIB_NUM_FINGERS]);

/**
 * @brief Start a new calibration sequence (begins at phase 0: NONE).
 * Call calibration_update() every loop iteration while active.
 */
void calibration_start(void);

/**
 * @brief Feed current ADC values into the running calibration.
 *
 * @param adc           Current raw 12-bit ADC values [index, middle, ring, pinky].
 * @param profiles_out  Filled with all 5 gesture profiles when return == 10.
 * @return  0   : in progress.
 *          N   : phase N-1 just completed (N=1..5); next phase starting automatically.
 *          10  : all 5 phases done, profiles_out is valid — save + apply.
 *         -1   : not started (call calibration_start() first).
 */
int calibration_update(const uint16_t adc[CALIB_NUM_FINGERS],
                       uint16_t profiles_out[CALIB_NUM_GESTURES][CALIB_NUM_FINGERS]);

/** @return True while calibration is running. */
bool calibration_active(void);

/**
 * @brief Current gesture name being calibrated.
 * @return "NONE" / "WATER" / "WC" / "FOOD" / "HELP" / "Gata!" when idle.
 */
const char *calibration_status_line(void);

/** @return Index of the current calibration phase (0-4). */
uint8_t calibration_current_phase(void);

#endif /* CALIBRATION_H */
```

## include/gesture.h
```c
#ifndef GESTURE_H
#define GESTURE_H

#include <stdint.h>
#include <stdbool.h>
#include "frame_protocol.h"

/*
 * Flex sensor threshold fallback: ADC below this = finger bent.
 * Hardware: 3.3V -> 1k resistor -> ADC -> flex sensor -> GND.
 *   Extended: high resistance -> high ADC.
 *   Bent:     low resistance  -> low ADC.
 * Default 2048 is used only before a valid calibration profile is loaded.
 */
#define FLEX_THRESH       2048U

/*
 * Gesture must be stable for this many ms before being reported.
 * 1000 ms keeps reporting deliberate while still feeling responsive.
 */
#define GESTURE_STABLE_MS  1000U

/**
 * @brief Load per-finger calibration profiles.
 *
 * open_avg[i]: ADC average when finger i is fully extended (NONE phase).
 * fist_avg[i]: ADC average when finger i is bent in its target gesture:
 *   [0] = index  finger bent ADC (WATER phase)
 *   [1] = middle finger bent ADC (WC phase)
 *   [2] = ring   finger bent ADC (FOOD phase)
 *   [3] = pinky  finger bent ADC (HELP phase)
 *
 * After this call, gesture_classify() uses normalized hysteresis scoring.
 * Before this call it falls back to binary FLEX_THRESH comparison.
 */
bool gesture_set_profiles(const uint16_t open_avg[4], const uint16_t fist_avg[4]);

/** @return True if calibration profiles have been loaded. */
bool gesture_has_profiles(void);

/**
 * @brief Classify a gesture from 4 ADC flex sensor values.
 *
 * With profiles: each finger gets a 0-100 bent score with hysteresis bands
 * (score > 65 = bent sticky, score < 35 = extended sticky, in between = keep state).
 * Current accepted masks:
 * WATER(0001 or 1110), WC(0011), FOOD(0111), HELP(1111).
 *
 * Without profiles: binary FLEX_THRESH fallback.
 *
 * @param adc  [index, middle, ring, pinky] 12-bit ADC values.
 * @return Detected gesture_id_t.
 */
gesture_id_t gesture_classify(const uint16_t adc[4]);

/** @return Last bent-finger mask computed by gesture_classify(). */
uint8_t gesture_last_bent_mask(void);

/**
 * @brief Return a human-readable name for a gesture.
 */
const char *gesture_name(gesture_id_t g);

#endif /* GESTURE_H */
```

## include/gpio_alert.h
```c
#ifndef GPIO_ALERT_H
#define GPIO_ALERT_H

#include <stdbool.h>

/**
 * GPIO emergency backup channel — ESP32 side.
 *
 * Hardware:
 *   GPIO18 (ALERT_IN)  <- wire <- STM32 PB0 (ALERT_OUT)
 *   GPIO19 (ACK_OUT)   -> wire -> STM32 PB1 (ACK_IN)
 *
 * Protocol:
 *   ESP32 watches GPIO18 for rising edge (interrupt driven).
 *   When ALERT detected: sends BLE emergency notification,
 *   raises GPIO19 (ACK) for 200 ms, then clears it.
 */

/** Initialise GPIO pins + interrupt. Call once during boot. */
int gpio_alert_init(void);

/**
 * Poll function — call from main loop.
 * Returns true if an unhandled ALERT was detected since last call.
 * Automatically asserts ACK for 200 ms and clears the flag.
 */
bool gpio_alert_poll(void);

#endif /* GPIO_ALERT_H */
```

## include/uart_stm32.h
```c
#ifndef UART_STM32_H
#define UART_STM32_H

#include <stdint.h>
#include "frame_protocol.h"

/**
 * @brief Initialize UART2 device for STM32 communication.
 * @return 0 on success, negative errno on failure.
 */
int uart_stm32_init(void);

/**
 * @brief Poll one byte from STM32 UART (non-blocking).
 * @param b  Output byte.
 * @return 0 if byte available, non-zero if no byte.
 */
int uart_stm32_poll_byte(uint8_t *b);

/**
 * @brief Send HMAC-only SESSION_HELLO to STM32.
 */
void uart_stm32_send_session_hello(uint32_t session_nonce);

/**
 * @brief Send a STATUS_ACK frame to STM32 mirroring the received SEQ.
 * @param seq  Sequence number from the received frame.
 */
void uart_stm32_send_ack(uint8_t seq);

/**
 * @brief Send a HEARTBEAT frame to STM32 (sequence managed internally).
 */
void uart_stm32_send_heartbeat(void);

/**
 * @brief Send CMD_CAREGIVER_ACK to STM32 (triggers OLED+buzz+motor feedback).
 * @param gesture_id  The gesture_id_t that was confirmed by the caregiver.
 */
void uart_stm32_send_caregiver_ack(uint8_t gesture_id);

/**
 * @brief Send CMD_OLED_TEXT to STM32 (show 6-char message on OLED line 2).
 * @param text  Up to 6 ASCII characters (null-terminated, truncated if longer).
 */
void uart_stm32_send_oled_text(const char *text);

/**
 * @brief Send CMD_HAPTIC_BUZZ to STM32.
 * @param duration_ms  Buzz duration in ms (rounded to nearest 10 ms, max 2550 ms).
 */
void uart_stm32_send_haptic_buzz(uint32_t duration_ms);

/**
 * @brief Send CMD_HAPTIC_VIBRATE to STM32.
 * @param duration_ms  Vibration duration in ms (rounded to nearest 10 ms).
 */
void uart_stm32_send_haptic_vibrate(uint32_t duration_ms);

/**
 * @brief Send CMD_GESTURE_FEEDBACK to STM32.
 * Triggers the per-gesture unique haptic+OLED pattern on STM32.
 * @param gesture_id  Recognized gesture (gesture_id_t cast to uint8_t).
 */
void uart_stm32_send_gesture_feedback(uint8_t gesture_id);

/**
 * @brief Send CMD_OLED_CALIB to STM32 — shows live calibration display.
 *
 * @param state  0..3 = OPEN (Gata:3/2/1/TINE!), 4..7 = FIST (same steps)
 * @param adc    Current 12-bit ADC values [4]; scaled >>4 before sending.
 */
void uart_stm32_send_calib_adc(uint8_t state, const uint16_t adc[4]);

#endif /* UART_STM32_H */
```

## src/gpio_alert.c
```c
#include "gpio_alert.h"

#include <zephyr/kernel.h>
#include <zephyr/drivers/gpio.h>
#include <zephyr/logging/log.h>

LOG_MODULE_REGISTER(gpio_alert, LOG_LEVEL_INF);

/* DT aliases defined in overlay:
 *   alert-in  -> GPIO18 (receives ALERT from STM32 PB0)
 *   ack-out   -> GPIO19 (sends ACK to STM32 PB1)
 */
#define ALERT_IN_NODE DT_ALIAS(alert_in)
#define ACK_OUT_NODE  DT_ALIAS(ack_out)

static const struct gpio_dt_spec s_alert_in =
    GPIO_DT_SPEC_GET(ALERT_IN_NODE, gpios);
static const struct gpio_dt_spec s_ack_out =
    GPIO_DT_SPEC_GET(ACK_OUT_NODE, gpios);

static volatile bool s_alert_flag;
static struct gpio_callback s_alert_cb;

static void alert_isr(const struct device *dev, struct gpio_callback *cb,
                      uint32_t pins)
{
    ARG_UNUSED(dev);
    ARG_UNUSED(cb);
    ARG_UNUSED(pins);
    s_alert_flag = true;
}

int gpio_alert_init(void)
{
    if (!gpio_is_ready_dt(&s_alert_in)) {
        LOG_ERR("ALERT_IN (GPIO18) not ready");
        return -ENODEV;
    }
    if (!gpio_is_ready_dt(&s_ack_out)) {
        LOG_ERR("ACK_OUT (GPIO19) not ready");
        return -ENODEV;
    }

    (void)gpio_pin_configure_dt(&s_alert_in, GPIO_INPUT | GPIO_PULL_DOWN);
    (void)gpio_pin_configure_dt(&s_ack_out,  GPIO_OUTPUT_INACTIVE);

    gpio_init_callback(&s_alert_cb, alert_isr, BIT(s_alert_in.pin));
    (void)gpio_add_callback(s_alert_in.port, &s_alert_cb);
    (void)gpio_pin_interrupt_configure_dt(&s_alert_in,
                                          GPIO_INT_EDGE_RISING);

    LOG_INF("GPIO alert init OK (GPIO18=IN GPIO19=OUT)");
    return 0;
}

bool gpio_alert_poll(void)
{
    if (!s_alert_flag) {
        return false;
    }
    s_alert_flag = false;

    LOG_WRN("ALERT pin raised by STM32 — emergency gesture detected!");

    /* Pulse ACK high for 200 ms so STM32 knows we got it. */
    (void)gpio_pin_set_dt(&s_ack_out, 1);
    k_msleep(200);
    (void)gpio_pin_set_dt(&s_ack_out, 0);

    return true;
}
```
